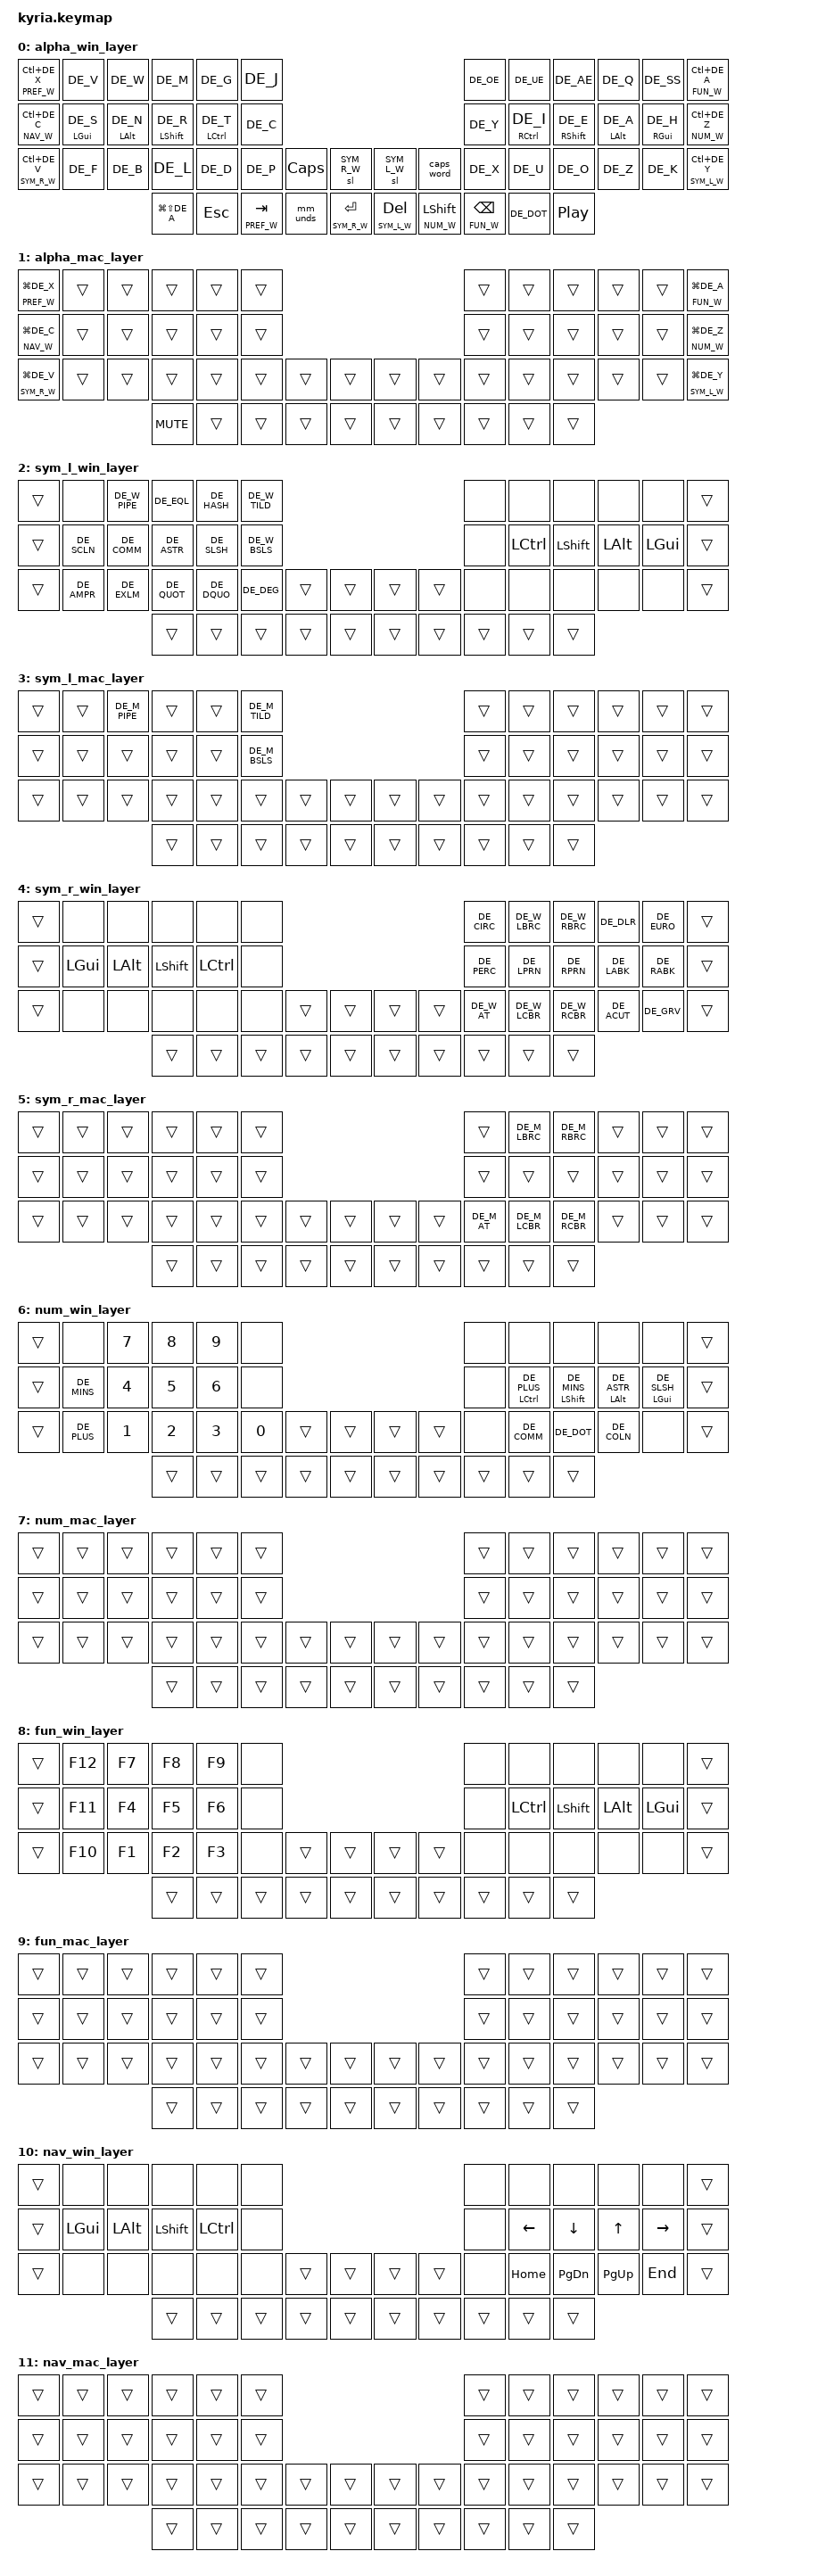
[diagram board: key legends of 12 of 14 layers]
/*
 * Copyright (c) 2020 The ZMK Contributors
 *
 * SPDX-License-Identifier: MIT
 */

#include <behaviors.dtsi>
#include <dt-bindings/zmk/bt.h>
#include <dt-bindings/zmk/keys.h>
#include <dt-bindings/zmk/outputs.h>

#include "german-keymap.h"

// Global sticky timeout
#define STICKY_TIMEOUT 10000

// Encoders
&sensors        { triggers-per-rotation = <30>; };
&left_encoder   { steps = <60>; };
&right_encoder  { steps = <60>; };

// None/Trans
#define _____ &none
#define t____ &trans

// Layers
#define ALPHA_W 0
#define ALPHA_M 1

#define SYM_L_W 2
#define SYM_L_M 3

#define SYM_R_W 4
#define SYM_R_M 5

#define NUM_W   6
#define NUM_M   7

#define FUN_W   8
#define FUN_M   9

#define NAV_W   10
#define NAV_M   11

#define PREF_W  12
#define PREF_M  13


&sk { release-after-ms = <STICKY_TIMEOUT>; };
&sl { release-after-ms = <STICKY_TIMEOUT>; };
&caps_word {
  continue-list = <LSHFT RSHIFT DE_UNDS DE_MINS DE_PLUS DE_AE DE_OE DE_UE BSPC>;
};

/ {
    combos {
        compatible = "zmk,combos";
        combo_bspc {
            timeout-ms = <50>;
            key-positions = <31 44>;
            bindings = <&kp BSPC>;
        };
    };
};

/ {
    behaviors {
        hm: homerow_mods {
            compatible = "zmk,behavior-hold-tap";
            #binding-cells = <2>;
            tapping-term-ms = <300>;
            quick_tap_ms = <0>;
            flavor = "tap-preferred";
            bindings = <&kp>, <&kp>;
        };
        skq: sticky_key_quick_release {
            compatible = "zmk,behavior-sticky-key";
            #binding-cells = <1>;
            bindings = <&kp>;
            release-after-ms = <STICKY_TIMEOUT>;
            quick-release;
        };
		ltqt: layer_tap_quick_tap {
			compatible = "zmk,behavior-hold-tap";
			#binding-cells = <2>;
			flavor = "tap-preferred";
			tapping-term-ms = <200>;
            quick_tap_ms = <300>;
			bindings = <&mo>, <&kp>;
		};
        lst: layer_sticky_tap {
            compatible = "zmk,behavior-hold-tap";
            #binding-cells = <2>;
            tapping-term-ms = <175>;
            flavor = "tap-preferred";
            bindings = <&mo>, <&skq>;
        };
        mm_unds: mod_morph_underscore {
            compatible = "zmk,behavior-mod-morph";
            #binding-cells = <0>;
            bindings = <&lt NAV_W SPACE>, <&kp DE_UNDS>;
            mods = <(MOD_LSFT|MOD_RSFT)>;
        };
    };

    conditional_layers {
        compatible = "zmk,conditional-layers";
        sym_l_mac {
            if-layers = <ALPHA_M SYM_L_W>;
            then-layer = <SYM_L_M>;
        };
        sym_r_mac {
            if-layers = <ALPHA_M SYM_R_W>;
            then-layer = <SYM_R_M>;
        };
        num_mac {
            if-layers = <ALPHA_M NUM_W>;
            then-layer = <NUM_M>;
        };
        fun_mac {
            if-layers = <ALPHA_M FUN_W>;
            then-layer = <FUN_M>;
        };
        nav_mac {
            if-layers = <ALPHA_M NAV_W>;
            then-layer = <NAV_M>;
        };
        pref_mac {
            if-layers = <ALPHA_M PREF_W>;
            then-layer = <PREF_M>;
        };
    };

    keymap {
        compatible = "zmk,keymap";

        alpha_win_layer {
            bindings = <
            &lt PREF_W LC(DE_X)   &kp DE_V       &kp DE_W       &kp DE_M          &kp DE_G        &kp DE_J                                                                              &kp DE_OE         &kp DE_UE       &kp DE_AE       &kp DE_Q       &kp DE_SS      &lt FUN_W LC(DE_A)
            &lt NAV_W LC(DE_C)    &hm LGUI DE_S  &hm LALT DE_N  &hm LSHFT DE_R    &hm LCTRL DE_T  &kp DE_C                                                                              &kp DE_Y          &hm RCTRL DE_I  &hm RSHFT DE_E  &hm LALT DE_A  &hm RGUI DE_H  &lt NUM_W LC(DE_Z)
            &lt SYM_R_W LC(DE_V)  &kp DE_F       &kp DE_B       &kp DE_L          &kp DE_D        &kp DE_P          &kp CAPS  &sl SYM_R_W          &sl SYM_L_W        &caps_word        &kp DE_X          &kp DE_U        &kp DE_O        &kp DE_Z       &kp DE_K       &lt SYM_L_W LC(DE_Y)
                                                                &kp LG(LS(DE_A))  &kp ESC         &ltqt PREF_W TAB  &mm_unds  &ltqt SYM_R_W RET    &ltqt SYM_L_W DEL  &lst NUM_W LSHFT  &ltqt FUN_W BSPC  &kp DE_DOT      &kp C_PP
            >;
            sensor-bindings = <&inc_dec_kp C_PREV C_NEXT &inc_dec_kp C_VOL_DN C_VOL_UP>;
        };
        alpha_mac_layer {
            bindings = <
            &lt PREF_W LG(DE_X)   t____  t____       t____  t____  t____                                t____  t____  t____  t____  t____  &lt FUN_W LG(DE_A)
            &lt NAV_W LG(DE_C)    t____  t____       t____  t____  t____                                t____  t____  t____  t____  t____  &lt NUM_W LG(DE_Z)
            &lt SYM_R_W LG(DE_V)  t____  t____       t____  t____  t____  t____  t____    t____  t____  t____  t____  t____  t____  t____  &lt SYM_L_W LG(DE_Y)
                                         &kp K_MUTE  t____  t____  t____  t____  t____    t____  t____  t____  t____
            >;
            sensor-bindings = <&inc_dec_kp t____ t____ &inc_dec_kp t____ t____>;
        };

        sym_l_win_layer {
            bindings = <
            t____  _____        &kp DE_W_PIPE  &kp DE_EQL   &kp DE_HASH  &kp DE_W_TILD                                _____  _____      _____      _____     _____     t____
            t____  &kp DE_SCLN  &kp DE_COMM    &kp DE_ASTR  &kp DE_SLSH  &kp DE_W_BSLS                                _____  &kp LCTRL  &kp LSHFT  &kp LALT  &kp LGUI  t____
            t____  &kp DE_AMPR  &kp DE_EXLM    &kp DE_QUOT  &kp DE_DQUO  &kp DE_DEG     t____  t____    t____  t____  _____  _____      _____      _____     _____     t____
                                               t____        t____        t____          t____  t____    t____  t____  t____  t____      t____
            >;
            sensor-bindings = <&inc_dec_kp t____ t____ &inc_dec_kp t____ t____>;
        };
        sym_l_mac_layer {
            bindings = <
            t____  t____  &kp DE_M_PIPE  t____  t____  &kp DE_M_TILD                                t____  t____  t____  t____  t____  t____
            t____  t____  t____          t____  t____  &kp DE_M_BSLS                                t____  t____  t____  t____  t____  t____
            t____  t____  t____          t____  t____  t____          t____  t____    t____  t____  t____  t____  t____  t____  t____  t____
                                         t____  t____  t____          t____  t____    t____  t____  t____  t____  t____
            >;
            sensor-bindings = <&inc_dec_kp t____ t____ &inc_dec_kp t____ t____>;
        };

        sym_r_win_layer {
            bindings = <
            t____  _____     _____     _____      _____      _____                                &kp DE_CIRC  &kp DE_W_LBRC  &kp DE_W_RBRC  &kp DE_DLR   &kp DE_EURO  t____
            t____  &kp LGUI  &kp LALT  &kp LSHFT  &kp LCTRL  _____                                &kp DE_PERC  &kp DE_LPRN    &kp DE_RPRN    &kp DE_LABK  &kp DE_RABK  t____
            t____  _____     _____     _____      _____      _____  t____  t____    t____  t____  &kp DE_W_AT  &kp DE_W_LCBR  &kp DE_W_RCBR  &kp DE_ACUT  &kp DE_GRV   t____
                                       t____      t____      t____  t____  t____    t____  t____  t____        t____          t____
            >;
            sensor-bindings = <&inc_dec_kp t____ t____ &inc_dec_kp PG_UP PG_DN>;
        };
        sym_r_mac_layer {
            bindings = <
            t____  t____  t____  t____  t____  t____                                t____        &kp DE_M_LBRC  &kp DE_M_RBRC  t____  t____  t____
            t____  t____  t____  t____  t____  t____                                t____        t____          t____          t____  t____  t____
            t____  t____  t____  t____  t____  t____  t____  t____    t____  t____  &kp DE_M_AT  &kp DE_M_LCBR  &kp DE_M_RCBR  t____  t____  t____
                                 t____  t____  t____  t____  t____    t____  t____  t____        t____          t____
            >;
            sensor-bindings = <&inc_dec_kp t____ t____ &inc_dec_kp PG_UP PG_DN>;
        };

        num_win_layer {
            bindings = <
            t____  _____        &kp N7  &kp N8  &kp N9  _____                                 _____  _____              _____              _____             _____             t____
            t____  &kp DE_MINS  &kp N4  &kp N5  &kp N6  _____                                 _____  &hm LCTRL DE_PLUS  &hm LSHFT DE_MINS  &hm LALT DE_ASTR  &hm LGUI DE_SLSH  t____
            t____  &kp DE_PLUS  &kp N1  &kp N2  &kp N3  &kp N0  t____  t____    t____  t____  _____  &kp DE_COMM        &kp DE_DOT         &kp DE_COLN       _____             t____
                                        t____   t____   t____   t____  t____    t____  t____  t____  t____              t____
            >;
            sensor-bindings = <&inc_dec_kp LS(TAB) TAB &inc_dec_kp t____ t____>;
        };
        num_mac_layer {
            bindings = <
            t____  t____  t____  t____  t____  t____                                t____  t____  t____  t____  t____  t____
            t____  t____  t____  t____  t____  t____                                t____  t____  t____  t____  t____  t____
            t____  t____  t____  t____  t____  t____  t____  t____    t____  t____  t____  t____  t____  t____  t____  t____
                                 t____  t____  t____  t____  t____    t____  t____  t____  t____  t____
            >;
            sensor-bindings = <&inc_dec_kp LS(TAB) TAB &inc_dec_kp t____ t____>;
        };

        fun_win_layer {
            bindings = <
            t____  &kp F12  &kp F7  &kp F8  &kp F9  _____                                _____  _____      _____      _____     _____     t____
            t____  &kp F11  &kp F4  &kp F5  &kp F6  _____                                _____  &kp LCTRL  &kp LSHFT  &kp LALT  &kp LGUI  t____
            t____  &kp F10  &kp F1  &kp F2  &kp F3  _____  t____  t____    t____  t____  _____  _____      _____      _____     _____     t____
                                    t____   t____   t____  t____  t____    t____  t____  t____  t____      t____
            >;
            sensor-bindings = <&inc_dec_kp LS(F3) F3 &inc_dec_kp LG(PG_UP) LG(PG_DN)>;
        };
        fun_mac_layer {
            bindings = <
            t____  t____  t____  t____  t____  t____                                t____  t____  t____  t____  t____  t____
            t____  t____  t____  t____  t____  t____                                t____  t____  t____  t____  t____  t____
            t____  t____  t____  t____  t____  t____  t____  t____    t____  t____  t____  t____  t____  t____  t____  t____
                                 t____  t____  t____  t____  t____    t____  t____  t____  t____  t____
            >;
            sensor-bindings = <&inc_dec_kp LG(LS(DE_G)) LG(DE_G) &inc_dec_kp LG(PG_UP) LG(PG_DN)>;
        };

        nav_win_layer {
            bindings = <
            t____  _____     _____     _____      _____      _____                                _____  _____     _____      _____      _____      t____
            t____  &kp LGUI  &kp LALT  &kp LSHFT  &kp LCTRL  _____                                _____  &kp LEFT  &kp DOWN   &kp UP     &kp RIGHT  t____
            t____  _____     _____     _____      _____      _____  t____  t____    t____  t____  _____  &kp HOME  &kp PG_DN  &kp PG_UP  &kp END    t____
                                       t____      t____      t____  t____  t____    t____  t____  t____  t____     t____
            >;
            sensor-bindings = <&inc_dec_kp LA(LEFT) LA(RIGHT) &inc_dec_kp LEFT RIGHT>;
        };
        nav_mac_layer {
            bindings = <
            t____  t____  t____  t____  t____  t____                                t____  t____  t____  t____  t____  t____
            t____  t____  t____  t____  t____  t____                                t____  t____  t____  t____  t____  t____
            t____  t____  t____  t____  t____  t____  t____  t____    t____  t____  t____  t____  t____  t____  t____  t____
                                 t____  t____  t____  t____  t____    t____  t____  t____  t____  t____
            >;
            sensor-bindings = <&inc_dec_kp LG(LEFT) LG(RIGHT) &inc_dec_kp LEFT RIGHT>;
        };

        pref_win_layer {
            bindings = <
            _____  _____  _____  _____  _____  _____                                &bt BT_CLR    _____         _____         &out OUT_TOG  _____         _____
            _____  _____  _____  _____  _____  _____                                &bt BT_SEL 1  &bt BT_SEL 2  &bt BT_SEL 3  &bt BT_SEL 4  &bt BT_SEL 5  _____
            _____  _____  _____  _____  _____  _____  _____  _____    _____  _____  &to ALPHA_M   &to ALPHA_W   _____         _____         _____         _____
                                 _____  _____  _____  _____  _____    _____  _____  _____         _____         _____
            >;
            sensor-bindings = <&inc_dec_kp LC(DE_Z) LC(DE_Y) &inc_dec_kp UP DOWN>;
        };
        pref_mac_layer {
            bindings = <
            t____  t____  t____  t____  t____  t____                                t____  t____  t____  t____  t____  t____
            t____  t____  t____  t____  t____  t____                                t____  t____  t____  t____  t____  t____
            t____  t____  t____  t____  t____  t____  t____  t____    t____  t____  t____  t____  t____  t____  t____  t____
                                 t____  t____  t____  t____  t____    t____  t____  t____  t____  t____
            >;
            sensor-bindings = <&inc_dec_kp LG(DE_Z) LG(DE_Y) &inc_dec_kp UP DOWN>;
        };
    };
};
